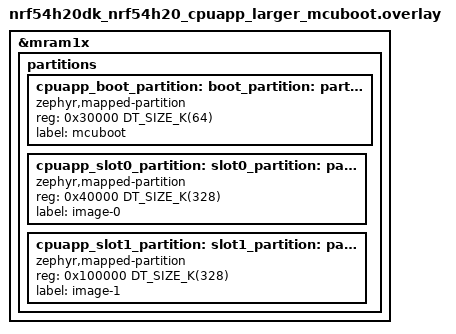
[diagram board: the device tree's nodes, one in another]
/*
 * Copyright (c) 2026 Nordic Semiconductor ASA
 *
 * SPDX-License-Identifier: LicenseRef-Nordic-5-Clause
 *
 */

#include "../dts/nrf54h20dk_nrf54h20_bootchain.dtsi"

/delete-node/ &cpuapp_boot_partition;
/delete-node/ &cpuapp_slot0_partition;
/delete-node/ &cpuapp_slot1_partition;

&mram1x {
	partitions {
		cpuapp_boot_partition: partition@30000 {
			compatible = "zephyr,mapped-partition";
			reg = <0x30000 DT_SIZE_K(64)>;
		};

		cpuapp_slot0_partition: partition@40000 {
			compatible = "zephyr,mapped-partition";
			reg = <0x40000 DT_SIZE_K(328)>;
		};

		cpuapp_slot1_partition: partition@100000 {
			compatible = "zephyr,mapped-partition";
			reg = <0x100000 DT_SIZE_K(328)>;
		};
	};
};

boot_partition: &cpuapp_boot_partition {
	label = "mcuboot";
};

slot0_partition: &cpuapp_slot0_partition {
	label = "image-0";
};

slot1_partition: &cpuapp_slot1_partition {
	label = "image-1";
};
